AUTOSAR XML (schema 00052)
package /adcm/AdaptiveApplicationSwComponentTypes
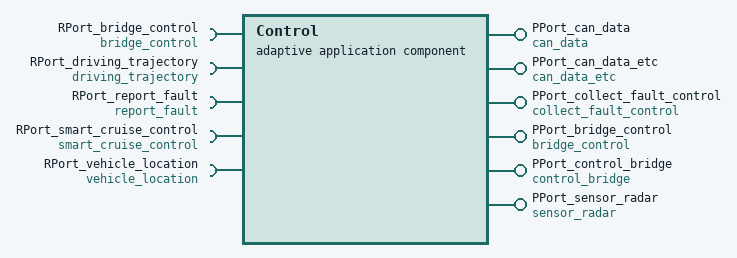
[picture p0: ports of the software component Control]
  adaptive application sw component type Control
    6 x provide port:
      PPort_can_data: provided-interface=can_data
      PPort_can_data_etc: provided-interface=can_data_etc
      PPort_collect_fault_control: provided-interface=collect_fault_control
      PPort_bridge_control: provided-interface=bridge_control
      PPort_control_bridge: provided-interface=control_bridge
      PPort_sensor_radar: provided-interface=sensor_radar
    5 x require port:
      RPort_bridge_control: required-interface=bridge_control
      RPort_driving_trajectory: required-interface=driving_trajectory
      RPort_report_fault: required-interface=report_fault
      RPort_smart_cruise_control: required-interface=smart_cruise_control
      RPort_vehicle_location: required-interface=vehicle_location
package /adcm/Executables
  executable Control: category=APPLICATION_LEVEL, minimum-timer-granularity=1000
    root sw component prototype Control: application-type=Control
